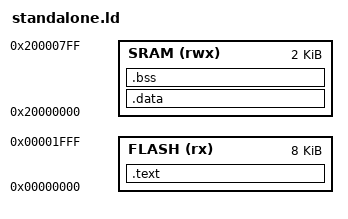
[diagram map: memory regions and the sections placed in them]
/******************************************************************************
 *
 * standalone.ld - Linker script for applications using startup.c and
 *                 DriverLib.
 *
 * Copyright (c) 2005,2006 Luminary Micro, Inc.  All rights reserved.
 *
 * Software License Agreement
 *
 * Luminary Micro, Inc. (LMI) is supplying this software for use solely and
 * exclusively on LMI's Stellaris Family of microcontroller products.
 *
 * The software is owned by LMI and/or its suppliers, and is protected under
 * applicable copyright laws.  All rights are reserved.  Any use in violation
 * of the foregoing restrictions may subject the user to criminal sanctions
 * under applicable laws, as well as to civil liability for the breach of the
 * terms and conditions of this license.
 *
 * THIS SOFTWARE IS PROVIDED "AS IS".  NO WARRANTIES, WHETHER EXPRESS, IMPLIED
 * OR STATUTORY, INCLUDING, BUT NOT LIMITED TO, IMPLIED WARRANTIES OF
 * MERCHANTABILITY AND FITNESS FOR A PARTICULAR PURPOSE APPLY TO THIS SOFTWARE.
 * LMI SHALL NOT, IN ANY CIRCUMSTANCES, BE LIABLE FOR SPECIAL, INCIDENTAL, OR
 * CONSEQUENTIAL DAMAGES, FOR ANY REASON WHATSOEVER.
 *
 *****************************************************************************/

MEMORY
{
    FLASH (rx) : ORIGIN = 0x00000000, LENGTH = 8K
    SRAM (rwx) : ORIGIN = 0x20000000, LENGTH = 2K
}

SECTIONS
{
    .text :
    {
        *(vectors)
        *(.text)
        *(.rodata*)
        *(.constdata*)
        _etext = .;
    } > FLASH

    .data : AT (ADDR(.text) + SIZEOF(.text))
    {
        _data = .;
        *(vtable)
        *(.data)
        _edata = .;
    } > SRAM

    .bss :
    {
        _bss = .;
        *(.bss)
        _ebss = .;
    } > SRAM
}
